# MSS_TRNG register map
Vendor: Texas Instruments
Peripheral module from a debugger description file (folder radar).
Registers are 32-bit, access per field, no defined reset value unless marked. A register's access mark holds for its fields unless they carry their own. Offsets are as the file gives them; lines under a group give offsets from that group; [hi:lo] are bit positions; {n}, {i} and the like mark numbered series; 'fields as' and 'values as' point back to an identical list; <NAME> marks a mode.

## MSS_TRNG
0x00 TRNG_OUTPUT_L_1 ro
  [31:0] RNG_OUT_L — Least significant word half of 64-bit word of random data, only valid when the ‘ready’ bit in the TRNG_STATUS register has value ‘1’.
0x04 TRNG_OUTPUT_H ro
  [31:0] RNG_OUT_H — Most significant word half of 64-bit word of random data, only valid when the ‘ready’ bit in the TRNG_STATUS register has value ‘1’.
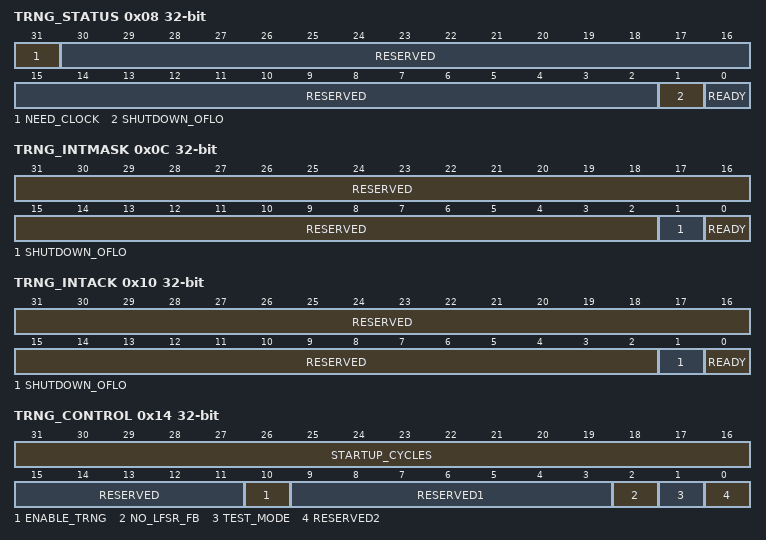
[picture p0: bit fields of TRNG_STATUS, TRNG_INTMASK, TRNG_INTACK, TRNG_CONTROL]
0x08 TRNG_STATUS ro
  [31] NEED_CLOCK — ‘1’ indicates that the TRNG is busy generating entropy or is in one of its test modes – clocks may not be turned off and the power supply voltage must be kept stable. This bit is a direct mirror of the ‘TRNG_need_clock’ output signal of the module.
  [30:2] RESERVED — Bits should be ignored on a read.
  [1] SHUTDOWN_OFLO — ‘1’ = the number of FROs shut down after a second ‘error event’ (i.e. the number of ‘1’ bits in the TRNG_ALARMSTOP register) has exceeded the threshold set by ‘shutdown_threshold’ in the TRNG_ERRORCNT register. Writing a ‘1’ to bit [1] of the TRNG_INTACK register clears this bit to ‘0’ again.
  [0] READY — 1’ = data is available in the TRNG_OUTPUT_H/L registers. Acknowledging this state by writing a ‘1’ to bit [0] of the TRNG_INTACK register clears this bit to ‘0’, if a new number is already available in the internal register of the TRNG, the number is directly clocked into the result register. In this case the status bit is asserted again, after one clock cycle
0x0C TRNG_INTMASK
  [31:2] RESERVED ro — Bits should be ignored on a read.
  [1] SHUTDOWN_OFLO rw — ‘1’ = allow the ‘shutdown_oflo’ bit in the TRNG_STATUS register to activate the (active LOW) ‘SINTREQUEST’ output.
  [0] READY rw — ‘1’ = allow the ‘ready’ bit in the TRNG_STATUS register to activate the (active LOW) ‘SINTREQUEST’ output.
0x10 TRNG_INTACK wo
  [31:2] RESERVED — Bits should be ignored on a read.
  [1] SHUTDOWN_OFLO — Write a ‘1’ to clear the ‘shutdown_oflo’ bit in the TRNG_STATUS register. Need not be written with a ‘0’ after writing a ‘1’, always reads ‘0’.
  [0] READY — Write a ‘1’ to clear the ‘ready’ bit in the TRNG_STATUS register. Need not be written with a ‘0’ after writing a ‘1’, always reads ‘0’.
0x14 TRNG_CONTROL
  [31:16] STARTUP_CYCLES rw — This field determines the number of samples (between 2^8 and 2^24) taken to gather entropy from the FROs during startup. If the written value of this field is zero, the number of samples is 2^24, otherwise the number of samples equals the written value times 2^8. This field can only be written when ‘enable_trng’ was ‘0’ before the write.
  [15:11] RESERVED ro — Bits should be written with ‘0’ and should be ignored on a read.
  [10] ENABLE_TRNG rw — Setting this bit to ‘1’ starts the TRNG, gathering entropy from the FROs for the number of samples determined by the value in the ‘startup_cycles’ field. Resetting this bit to ‘0’ forces all TRNG logic back into the idle state immediately.
  [9:3] RESERVED1 ro — Bits should be written with ‘0’ and should be ignored on a read.
  [2] NO_LFSR_FB rw — ‘1’ = Remove XNOR feedback from the main LFSR, converting it into a normal shift register for the XOR-ed outputs of the FROs (shifting data in on the LSB side). A ‘1’ also forces the LFSR to sample continuously. This bit can only be set to ‘1’ when ‘test_mode’ is also set to ‘1’.
  [1] TEST_MODE rw — ‘1’ = Enables access to the TRNG_COUNT and TRNG_LFSR_L/M/H registers (the latter are cleared before enabling access) and keep ‘TRNG_need_clock’ output active HIGH for testing purposes.
  [0] RESERVED2 rw — Bits should be written with ‘0’ and should be ignored on a read.
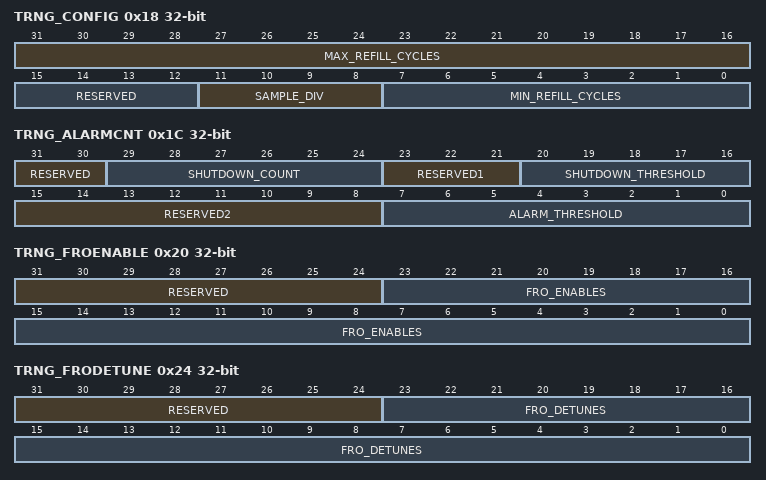
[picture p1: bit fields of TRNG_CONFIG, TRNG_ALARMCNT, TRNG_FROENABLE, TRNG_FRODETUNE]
0x18 TRNG_CONFIG
  [31:16] MAX_REFILL_CYCLES rw — This field determines the maximum number of samples (between 2^8 and 2^24) taken to re-generate entropy from the FROs after reading out a 64 bits random number. If the written value of this field is zero, the number of samples is 2^24, otherwise the number of samples equals the written value times 2^8. This field can only be modified while ‘enable_trng’ in TRNG_CONTROL is ‘0’.
  [15:12] RESERVED ro — Bits should be written with ‘0’ and should be ignored on a read.
  [11:8] SAMPLE_DIV rw — This field directly controls the number of CLK input cycles between samples taken from the FROs. Default value 0 indicates that samples are taken every CLK cycle, maximum value 15d takes one sample every 16 CLK cycles. This field must be set to a value such that the slowest FRO (even under worst-case conditions) has a cycle time less than twice the sample period. This field can only be modified while ‘enable_trng’ in TRNG_CONTROL is ‘0’.
  [7:0] MIN_REFILL_CYCLES rw — This field determines the minimum number of samples (between 2^6 and 2^24) taken to re-generate entropy from the FROs after reading out a 64 bits random number. If the value of this field is zero, the number of samples is fixed to the value determined by the ‘max_refill_cycles’ field, otherwise the minimum number of samples equals the written value times 64 (which can be up to 2^14). The number of samples defined here cannot be higher than the number defined by the ‘max_refill_cycles’ field (i.e. that field takes precedence). This field can only be modified while ‘enable_trng’ in TRNG_CONTROL is ‘0’.
0x1C TRNG_ALARMCNT
  [31:30] RESERVED ro — Bits should be written with ‘0’ and should be ignored on a read.
  [29:24] SHUTDOWN_COUNT rw — Read-only, indicates the number of ‘1’ bits in the TRNG_ALARMSTOP register. This field is 6 bits wide to allow up to 32 ‘ones’ to be indicated; the actual maximum value equals the number of FROs.
  [23:21] RESERVED1 ro — Bits should be written with ‘0’ and should be ignored on a read.
  [20:16] SHUTDOWN_THRESHOLD rw — Threshold setting for generating the ‘shutdown_oflo’ interrupt, which is activated when the ‘shutdown_count’ value in this register exceeds the value set here.
  [15:8] RESERVED2 ro — Bits should be written with ‘0’ and should be ignored on a read.
  [7:0] ALARM_THRESHOLD rw — Alarm detection threshold for the repeating pattern detectors on each FRO. An FRO ‘alarm event’ is declared when a repeating pattern (of up to four samples length) is detected continuously for the number of samples defined by this field’s value. Reset value 255d should keep the number of ‘alarm events’ to a manageable level.
0x20 TRNG_FROENABLE
  [31:24] RESERVED ro — Bits should be written with ‘0’ and should be ignored on a read.
  [23:0] FRO_ENABLES rw — Enable bits for the individual FROs, a ‘1’ in bit [n] enables FRO ‘n’. Default state is all ‘1’s to enable all FROs after power-up (note that they are not actually started up before the ‘enable_trng’ bit in the TRNG_CONTROL register is set to ‘1’). Bits are automatically forced to ‘0’ here (and cannot be written to ‘1’) while the corresponding bit in the TRNG_ALARMSTOP register has value ‘1’.
0x24 TRNG_FRODETUNE
  [31:24] RESERVED ro — Bits should be written with ‘0’ and should be ignored on a read.
  [23:0] FRO_DETUNES rw — De-tune bits for the individual FROs, a ‘1’ in bit [n] lets FRO ‘n’ run approximately 5% faster. The value of one of these bits may only be changed while the corresponding FRO is turned off (by temporarily writing a ‘0’ in the corresponding bit of the TRNG_FROENABLE register).
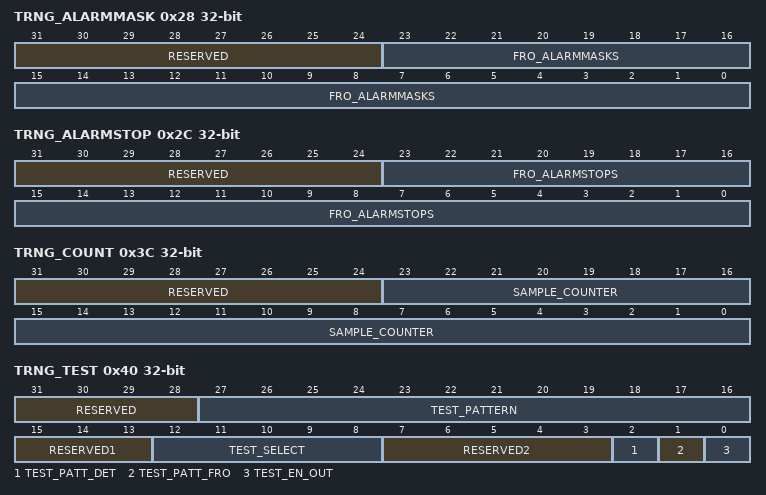
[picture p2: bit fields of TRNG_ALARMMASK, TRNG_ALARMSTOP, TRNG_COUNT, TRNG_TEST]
0x28 TRNG_ALARMMASK rw
  [31:24] RESERVED — Bits should be written with ‘0’ and should be ignored on a read.
  [23:0] FRO_ALARMMASKS — Logging bits for the ‘alarm events’ of individual FROs. A ‘1’ in bit [n] indicates FRO ‘n’ experienced an ‘alarm event’.
0x2C TRNG_ALARMSTOP
  [31:24] RESERVED ro — Bits should be written with ‘0’ and should be ignored on a read.
  [23:0] FRO_ALARMSTOPS rw — Logging bits for the ‘alarm events’ of individual FROs, a ‘1’ in bit [n] indicates FRO ‘n’ experienced more than one ‘alarm event’ in quick succession and has been turned off. A ‘1’ in this field forces the corresponding bit in the TRNG_FROENABLE register to ‘0’.
0x30 TRNG_LFSR_L rw
  [31:0] LFSR_31_0 — Bits [31:0] of the main entropy accumulation LFSR. Register can only be accessed when ‘test_mode’ bit in TRNG_CONTROL is set to ‘1’, register contents will be cleared to zero before access is enabled.
0x34 TRNG_LFSR_M rw
  [31:0] LFSR_63_32 — Bits [63:32] of the main entropy accumulation LFSR. Register can only be accessed when ‘test_mode’ bit in TRNG_CONTROL is set to ‘1’, register contents will be cleared to zero before access is enabled.
0x38 TRNG_LFSR_H rw
  [31:0] LFSR_80_64 — Bits [80:64] of the main entropy accumulation LFSR. Register can only be accessed when ‘test_mode’ bit in TRNG_CONTROL is set to ‘1’, register contents will be cleared to zero before access is enabled. Note: [31:17] is reserved
0x3C TRNG_COUNT
  [31:24] RESERVED ro — Bits should be written with ‘0’ and should be ignored on a read.
  [23:0] SAMPLE_COUNTER rw — Sample counter used by control FSM. Counter can only be accessed when ‘test_mode’ bit in TRNG_CONTROL is set to ‘1’.
0x40 TRNG_TEST
  [31:28] RESERVED ro — Bits should be written with ‘0’ and should be ignored on a read.
  [27:16] TEST_PATTERN rw — Repeating sequence of bits to be fed into the selected FRO delay chain (‘test_patt_fro’ = ‘1’) and/or the selected FRO error detection circuit (‘test_patt_det’ = ‘1’). This field is rotated right over one bit once every sample period when either of these control bits is ‘1’, bit [16] is the actual pattern bit fed into the test target.
  [15:13] RESERVED1 ro — Bits should be written with ‘0’ and should be ignored on a read.
  [12:8] TEST_SELECT rw — Number of the FRO to be tested, value should be in range 0 – 23.
  [7:3] RESERVED2 ro — Bits should be written with ‘0’ and should be ignored on a read.
  [2] TEST_PATT_DET rw — ‘1’ = Repeatedly feed ‘test_pattern’ into the error detection circuit of the FRO selected by the ‘test_select’ field. This bit can only be set to ‘1’ when ‘test_mode’ in TRNG_CONTROL is ‘1’ too.
  [1] TEST_PATT_FRO rw — ‘1’ = Repeatedly feed ‘test_pattern’ into the delay chain of the FRO selected by the ‘test_select’ field by forcing the corresponding ‘TEST_fro_enable’ output LOW and forcing the corresponding ‘TEST_fro_testin’ output to the state of bit [16] of this register. This bit can only be set to ‘1’ when ‘test_mode’ in TRNG_CONTROL is ‘1’ too.
  [0] TEST_EN_OUT rw — ‘1’ = Enable the ‘tst_fro_clk_out’ output, connecting to the FRO selected by the ‘test_select’ field. This bit can only be set to ‘1’ when ‘test_mode’ in TRNG_CONTROL is ‘1’ too.
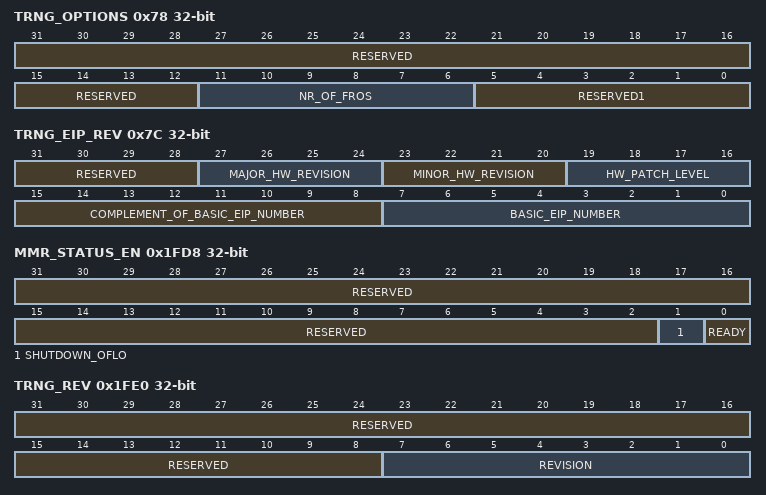
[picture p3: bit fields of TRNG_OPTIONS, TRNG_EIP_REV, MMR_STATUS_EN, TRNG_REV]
0x78 TRNG_OPTIONS ro
  [31:12] RESERVED — Bits should be written with ‘0’ and should be ignored on a read.
  [11:6] NR_OF_FROS — Number of FROs implemented in this TRNG, value 24 (decimal) for now.
  [5:0] RESERVED1 — Bits should be written with ‘0’ and should be ignored on a read.
0x7C TRNG_EIP_REV ro
  [31:28] RESERVED — Bits should be written with ‘0’ and should be ignored on a read.
  [27:24] MAJOR_HW_REVISION — 4 bits binary encoding of the major hardware revision number.
  [23:20] MINOR_HW_REVISION — 4 bits binary encoding of the minor hardware revision number.
  [19:16] HW_PATCH_LEVEL — 4 bits binary encoding of the hardware patch level, initial release will carry value zero.
  [15:8] COMPLEMENT_OF_BASIC_EIP_NUMBER — Bit-by-bit logic complement of bits [7:0], EIP 75t gives 0xB4.
  [7:0] BASIC_EIP_NUMBER — 8 bits binary encoding of the EIP number, EIP 75t gives 0x4B.
0x1FD8 MMR_STATUS_EN ro
  [31:2] RESERVED — Bits should be written with ‘0’ and should be ignored on a read.
  [1] SHUTDOWN_OFLO — ‘1’ = the number of FROs shut down after a second ‘error event’ (i.e. the number of ‘1’ bits in the TRNG_ALARMSTOP register) has exceeded the threshold set by ‘shutdown_threshold’ in the TRNG_ERRORCNT register. Writing a ‘1’ to bit [1] of the TRNG_INTACK register clears this bit to ‘0’ again.
  [0] READY — 1’ = data is available in the TRNG_OUTPUT_H/L registers. Acknowledging this state by writing a ‘1’ to bit [0] of the TRNG_INTACK register clears this bit to ‘0’, if a new number is already available in the internal register of the TRNG, the number is directly clocked into the result register. In this case the status bit is asserted again, after one clock cycle
0x1FE0 TRNG_REV ro
  [31:8] RESERVED — Bits should be written with ‘0’ and should be ignored on a read.
  [7:0] REVISION — TRNG Revision number
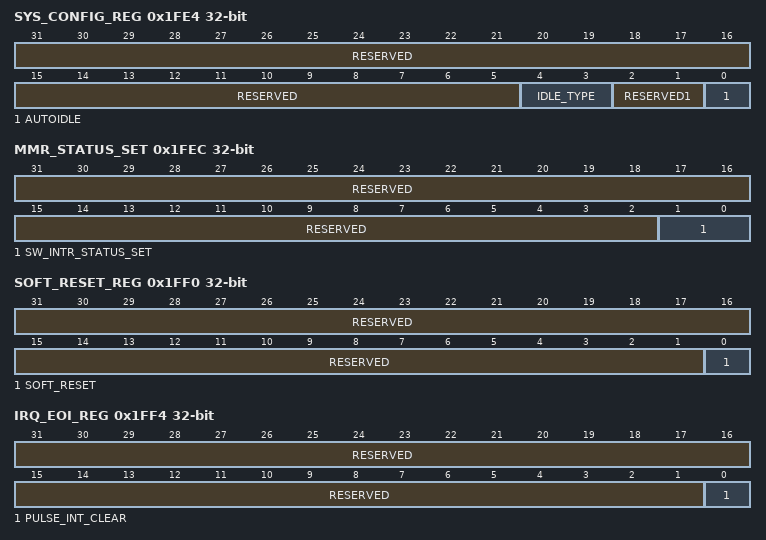
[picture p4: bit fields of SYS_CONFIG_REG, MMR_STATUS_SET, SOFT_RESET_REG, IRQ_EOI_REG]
0x1FE4 SYS_CONFIG_REG
  [31:5] RESERVED ro — Bits should be written with ‘0’ and should be ignored on a read.
  [4:3] IDLE_TYPE rw — To Specity the IDLE Type
  [2:1] RESERVED1 rw — Bits should be written with ‘0’ and should be ignored on a read.
  [0] AUTOIDLE rw — Auto IDLE Mode
0x1FEC MMR_STATUS_SET rw
  [31:2] RESERVED — Bits should be written with ‘0’ and should be ignored on a read.
  [1:0] SW_INTR_STATUS_SET — software interrupt set
0x1FF0 SOFT_RESET_REG
  [31:1] RESERVED ro — Bits should be written with ‘0’ and should be ignored on a read.
  [0] SOFT_RESET rw — sofware reset control
0x1FF4 IRQ_EOI_REG wo
  [31:1] RESERVED — Bits should be written with ‘0’ and should be ignored on a read.
  [0] PULSE_INT_CLEAR — Write only will clear the interrupt when asserted
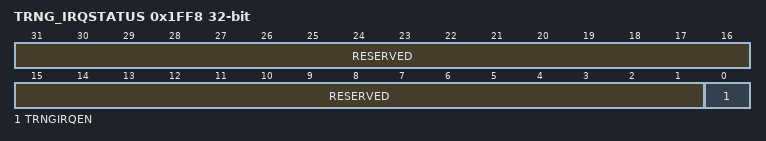
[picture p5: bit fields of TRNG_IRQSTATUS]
0x1FF8 TRNG_IRQSTATUS ro
  [31:1] RESERVED — Bits should be written with ‘0’ and should be ignored on a read.
  [0] TRNGIRQEN — TRNG interrupt status
